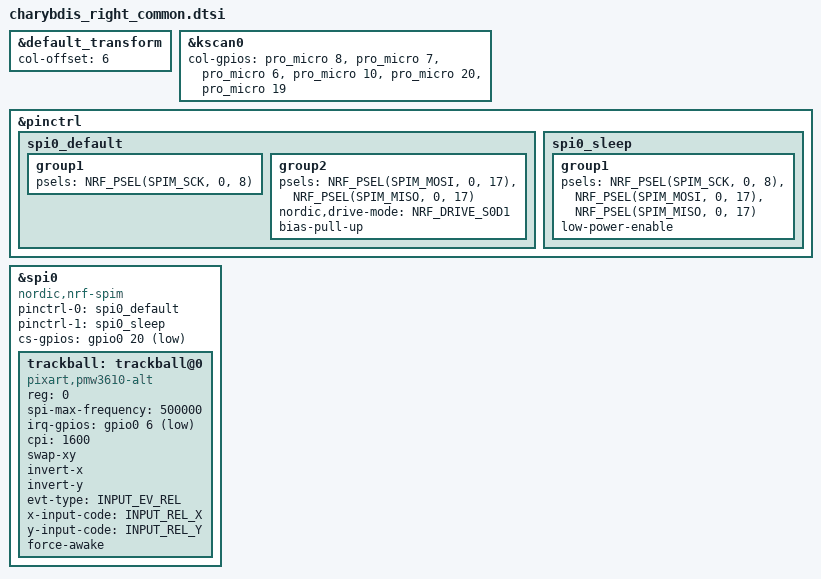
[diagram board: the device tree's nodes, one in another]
/*
 * Copyright (c) 2024 The ZMK Contributors
 * SPDX-License-Identifier: MIT
 *
 * Common hardware configuration for Charybdis right keyboard variants
 * Shared between charybdis_right_standalone and dongle_charybdis_right
 */

#include "charybdis.dtsi"
#include <zephyr/dt-bindings/input/input-event-codes.h>

&default_transform {
	col-offset = <6>;
};

&kscan0 {
	col-gpios
		= <&pro_micro 8 (GPIO_ACTIVE_HIGH | GPIO_PULL_DOWN)>
		, <&pro_micro 7 (GPIO_ACTIVE_HIGH | GPIO_PULL_DOWN)>
		, <&pro_micro 6 (GPIO_ACTIVE_HIGH | GPIO_PULL_DOWN)>
		, <&pro_micro 10 (GPIO_ACTIVE_HIGH | GPIO_PULL_DOWN)>
		, <&pro_micro 20 (GPIO_ACTIVE_HIGH | GPIO_PULL_DOWN)>
		, <&pro_micro 19 (GPIO_ACTIVE_HIGH | GPIO_PULL_DOWN)>
  ;
};

/*
 * PMW3610 uses 3-wire SPI: one bidirectional SDIO line, so MOSI and MISO are both
 * psel'd to P0.17. During a read the driver sends no tx data, so the nRF clocks out
 * the over-read character (CONFIG_SPI_NRFX_ORC, default 0xff). With the default
 * push-pull drive that means the MCU actively drives SDIO *high* for all 8 bits while
 * the sensor is trying to answer on the same wire -> the MCU wins the contention and
 * the driver reads back its own filler: "Incorrect product id 0xff".
 *
 * S0D1 makes the pad open-drain (drives 0, disconnects on 1), so clocking out 0xff
 * releases the line and lets the sensor drive it. bias-pull-up restores the idle high
 * level. SCK stays push-pull in its own group - it is unidirectional.
 */
&pinctrl {
    spi0_default: spi0_default {
        group1 {
            psels = <NRF_PSEL(SPIM_SCK, 0, 8)>;
        };
        group2 {
            psels = <NRF_PSEL(SPIM_MOSI, 0, 17)>,
                <NRF_PSEL(SPIM_MISO, 0, 17)>;
            nordic,drive-mode = <NRF_DRIVE_S0D1>;
            bias-pull-up;
        };
    };

    spi0_sleep: spi0_sleep {
        group1 {
            psels = <NRF_PSEL(SPIM_SCK, 0, 8)>,
                <NRF_PSEL(SPIM_MOSI, 0, 17)>,
                <NRF_PSEL(SPIM_MISO, 0, 17)>;
            low-power-enable;
        };
    };
};

&spi0 {
    status = "okay";
    compatible = "nordic,nrf-spim";
    pinctrl-0 = <&spi0_default>;
    pinctrl-1 = <&spi0_sleep>;
    pinctrl-names = "default", "sleep";
    cs-gpios = <&gpio0 20 GPIO_ACTIVE_LOW>;

    trackball: trackball@0 {
        status = "okay";
        compatible = "pixart,pmw3610-alt";
        reg = <0>;
        spi-max-frequency = <500000>;  // lowered from 2MHz for handwired signal-integrity margin (LSB bit errors -> 0x3f)
        irq-gpios = <&gpio0 6 (GPIO_ACTIVE_LOW | GPIO_PULL_UP)>;
        // Sample high and scale DOWN in the input processors, never up: the sensor
        // reports integer counts, so a multiplier >1 anywhere just magnifies the
        // quantisation step. The scalers divide with remainder accumulation
        // (input_processor_scaler.c), so dividing is lossless in aggregate.
        // Every divisor in charybdis_trackball_processors.dtsi is sized against this
        // value -- change one, change all four.
        cpi = <1600>;  // range 200-3200, step 200 (multiples of 200)
        swap-xy;
        invert-x;
        invert-y;
        evt-type = <INPUT_EV_REL>;
        x-input-code = <INPUT_REL_X>;
        y-input-code = <INPUT_REL_Y>;
        force-awake;
        /* keep the sensor awake while ZMK activity state is ACTIVE,
           fallback to normal downshift mode after ZMK goes into IDLE / SLEEP mode.
           thus, the sensor would be a `wakeup-source` */
        // force-awake-4ms-mode;
        /* while force-awake is acitvated, enable this mode to force sampling per
           4ms, where the default sampling rate is 8ms. */
        /* NOTE: apply this mode if you need 250Hz with direct USB connection. */
    };
};

